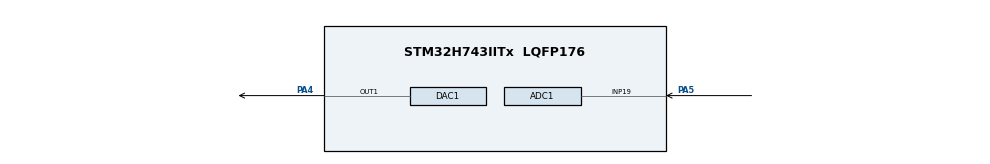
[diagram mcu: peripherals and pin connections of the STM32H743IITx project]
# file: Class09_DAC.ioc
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ADC1.Channel-3\#ChannelRegularConversion=ADC_CHANNEL_19
ADC1.ContinuousConvMode=DISABLE
ADC1.DiscontinuousConvMode=DISABLE
ADC1.NbrOfConversionFlag=1
ADC1.OffsetNumber-3\#ChannelRegularConversion=ADC_OFFSET_NONE
ADC1.Rank-3\#ChannelRegularConversion=1
ADC1.SamplingTime-3\#ChannelRegularConversion=ADC_SAMPLETIME_810CYCLES_5
ADC1.master=1
Mcu.Family=STM32H7
Mcu.Name=STM32H743IITx
Mcu.Package=LQFP176
NVIC.PriorityGroup=NVIC_PRIORITYGROUP_4
PA4.Signal=COMP_DAC11_group
PA5.Signal=ADCx_INP19
PH0-OSC_IN\ (PH0).Mode=HSE-External-Oscillator
PH0-OSC_IN\ (PH0).Signal=RCC_OSC_IN
PH1-OSC_OUT\ (PH1).Mode=HSE-External-Oscillator
PH1-OSC_OUT\ (PH1).Signal=RCC_OSC_OUT
ProjectManager.HeapSize=0x200
ProjectManager.StackSize=0x400
ProjectManager.TargetToolchain=MDK-ARM V5
RCC.ADCFreq_Value=150000000
RCC.APB1Freq_Value=100000000
RCC.APB2Freq_Value=100000000
RCC.APB3Freq_Value=100000000
RCC.APB4Freq_Value=100000000
RCC.CortexFreq_Value=400000000
RCC.D1PPRE=RCC_APB3_DIV2
RCC.D2PPRE1=RCC_APB1_DIV2
RCC.D2PPRE2=RCC_APB2_DIV2
RCC.D3PPRE=RCC_APB4_DIV2
RCC.DIVM1=2
RCC.DIVM2=2
RCC.DIVN1=64
RCC.DIVN2=12
RCC.DIVP2=1
RCC.HCLKFreq_Value=200000000
RCC.HPRE=RCC_HCLK_DIV2
RCC.PLLSourceVirtual=RCC_PLLSOURCE_HSE
RCC.SYSCLKFreq_VALUE=400000000
RCC.SYSCLKSource=RCC_SYSCLKSOURCE_PLLCLK
RCC.USBFreq_Value=400000000
SH.ADCx_INP19.0=ADC1_INP19,IN19-Single-Ended
SH.COMP_DAC11_group.0=DAC1_OUT1,DAC_OUT1
board=custom

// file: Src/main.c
/* USER CODE BEGIN Header */
/**
  ******************************************************************************
  * @file           : main.c
  * @brief          : Main program body
  ******************************************************************************
  ** This notice applies to any and all portions of this file
  * that are not between comment pairs USER CODE BEGIN and
  * USER CODE END. Other portions of this file, whether
  * inserted by the user or by software development tools
  * are owned by their respective copyright owners.
  *
  * COPYRIGHT(c) 2018 STMicroelectronics
  *
  * Redistribution and use in source and binary forms, with or without modification,
  * are permitted provided that the following conditions are met:
  *   1. Redistributions of source code must retain the above copyright notice,
  *      this list of conditions and the following disclaimer.
  *   2. Redistributions in binary form must reproduce the above copyright notice,
  *      this list of conditions and the following disclaimer in the documentation
  *      and/or other materials provided with the distribution.
  *   3. Neither the name of STMicroelectronics nor the names of its contributors
  *      may be used to endorse or promote products derived from this software
  *      without specific prior written permission.
  *
  * THIS SOFTWARE IS PROVIDED BY THE COPYRIGHT HOLDERS AND CONTRIBUTORS "AS IS"
  * AND ANY EXPRESS OR IMPLIED WARRANTIES, INCLUDING, BUT NOT LIMITED TO, THE
  * IMPLIED WARRANTIES OF MERCHANTABILITY AND FITNESS FOR A PARTICULAR PURPOSE ARE
  * DISCLAIMED. IN NO EVENT SHALL THE COPYRIGHT HOLDER OR CONTRIBUTORS BE LIABLE
  * FOR ANY DIRECT, INDIRECT, INCIDENTAL, SPECIAL, EXEMPLARY, OR CONSEQUENTIAL
  * DAMAGES (INCLUDING, BUT NOT LIMITED TO, PROCUREMENT OF SUBSTITUTE GOODS OR
  * SERVICES; LOSS OF USE, DATA, OR PROFITS; OR BUSINESS INTERRUPTION) HOWEVER
  * CAUSED AND ON ANY THEORY OF LIABILITY, WHETHER IN CONTRACT, STRICT LIABILITY,
  * OR TORT (INCLUDING NEGLIGENCE OR OTHERWISE) ARISING IN ANY WAY OUT OF THE USE
  * OF THIS SOFTWARE, EVEN IF ADVISED OF THE POSSIBILITY OF SUCH DAMAGE.
  *
  ******************************************************************************
  */
/* USER CODE END Header */

#include "main.h"

ADC_HandleTypeDef hadc1;

DAC_HandleTypeDef hdac1;

void SystemClock_Config(void);
static void MX_GPIO_Init(void);
static void MX_DAC1_Init(void);
static void MX_ADC1_Init(void);

/* USER CODE BEGIN 0 */
unsigned int adc_v;
unsigned int dac_v = 0;
float v;
/* USER CODE END 0 */

int main(void)
{

  /* MCU Configuration--------------------------------------------------------*/

  /* Reset of all peripherals, Initializes the Flash interface and the Systick. */
  HAL_Init();

  /* Configure the system clock */
  SystemClock_Config();

  /* Initialize all configured peripherals */
  MX_GPIO_Init();
  MX_DAC1_Init();
  MX_ADC1_Init();
  /* USER CODE BEGIN 2 */
	HAL_DAC_Start(&hdac1,DAC_CHANNEL_1);
  /* USER CODE END 2 */

  /* Infinite loop */
  while (1)
  {

    /* USER CODE BEGIN 3 */
		dac_v += 1;
		HAL_DAC_SetValue(&hdac1,DAC1_CHANNEL_1,DAC_ALIGN_12B_R,dac_v);
		HAL_ADC_Start(&hadc1);
		adc_v = HAL_ADC_GetValue(&hadc1);
		v = 3.3 * (adc_v / 65536.0);
  }
  /* USER CODE END 3 */
}

void SystemClock_Config(void)
{
  RCC_OscInitTypeDef RCC_OscInitStruct = {0};
  RCC_ClkInitTypeDef RCC_ClkInitStruct = {0};
  RCC_PeriphCLKInitTypeDef PeriphClkInitStruct = {0};

  /**Supply configuration update enable
  */
  MODIFY_REG(PWR->CR3, PWR_CR3_SCUEN, 0);
  /**Configure the main internal regulator output voltage
  */
  __HAL_PWR_VOLTAGESCALING_CONFIG(PWR_REGULATOR_VOLTAGE_SCALE1);

  while ((PWR->D3CR & (PWR_D3CR_VOSRDY)) != PWR_D3CR_VOSRDY)
  {

  }
  /**Macro to configure the PLL clock source
  */
  __HAL_RCC_PLL_PLLSOURCE_CONFIG(RCC_PLLSOURCE_HSE);
  /**Initializes the CPU, AHB and APB busses clocks
  */
  RCC_OscInitStruct.OscillatorType = RCC_OSCILLATORTYPE_HSE;
  RCC_OscInitStruct.HSEState = RCC_HSE_ON;
  RCC_OscInitStruct.PLL.PLLState = RCC_PLL_ON;
  RCC_OscInitStruct.PLL.PLLSource = RCC_PLLSOURCE_HSE;
  RCC_OscInitStruct.PLL.PLLM = 2;
  RCC_OscInitStruct.PLL.PLLN = 64;
  RCC_OscInitStruct.PLL.PLLP = 2;
  RCC_OscInitStruct.PLL.PLLQ = 2;
  RCC_OscInitStruct.PLL.PLLR = 2;
  RCC_OscInitStruct.PLL.PLLRGE = RCC_PLL1VCIRANGE_3;
  RCC_OscInitStruct.PLL.PLLVCOSEL = RCC_PLL1VCOWIDE;
  RCC_OscInitStruct.PLL.PLLFRACN = 0;
  if (HAL_RCC_OscConfig(&RCC_OscInitStruct) != HAL_OK)
  {
    Error_Handler();
  }
  /**Initializes the CPU, AHB and APB busses clocks
  */
  RCC_ClkInitStruct.ClockType = RCC_CLOCKTYPE_HCLK|RCC_CLOCKTYPE_SYSCLK
                              |RCC_CLOCKTYPE_PCLK1|RCC_CLOCKTYPE_PCLK2
                              |RCC_CLOCKTYPE_D3PCLK1|RCC_CLOCKTYPE_D1PCLK1;
  RCC_ClkInitStruct.SYSCLKSource = RCC_SYSCLKSOURCE_PLLCLK;
  RCC_ClkInitStruct.SYSCLKDivider = RCC_SYSCLK_DIV1;
  RCC_ClkInitStruct.AHBCLKDivider = RCC_HCLK_DIV2;
  RCC_ClkInitStruct.APB3CLKDivider = RCC_APB3_DIV2;
  RCC_ClkInitStruct.APB1CLKDivider = RCC_APB1_DIV2;
  RCC_ClkInitStruct.APB2CLKDivider = RCC_APB2_DIV2;
  RCC_ClkInitStruct.APB4CLKDivider = RCC_APB4_DIV2;

  if (HAL_RCC_ClockConfig(&RCC_ClkInitStruct, FLASH_LATENCY_2) != HAL_OK)
  {
    Error_Handler();
  }
  PeriphClkInitStruct.PeriphClockSelection = RCC_PERIPHCLK_ADC;
  PeriphClkInitStruct.PLL2.PLL2M = 2;
  PeriphClkInitStruct.PLL2.PLL2N = 12;
  PeriphClkInitStruct.PLL2.PLL2P = 1;
  PeriphClkInitStruct.PLL2.PLL2Q = 2;
  PeriphClkInitStruct.PLL2.PLL2R = 2;
  PeriphClkInitStruct.PLL2.PLL2RGE = RCC_PLL2VCIRANGE_3;
  PeriphClkInitStruct.PLL2.PLL2VCOSEL = RCC_PLL2VCOMEDIUM;
  PeriphClkInitStruct.PLL2.PLL2FRACN = 0;
  PeriphClkInitStruct.AdcClockSelection = RCC_ADCCLKSOURCE_PLL2;
  if (HAL_RCCEx_PeriphCLKConfig(&PeriphClkInitStruct) != HAL_OK)
  {
    Error_Handler();
  }
}

static void MX_ADC1_Init(void)
{

  ADC_MultiModeTypeDef multimode = {0};
  ADC_ChannelConfTypeDef sConfig = {0};

  /**Common config
  */
  hadc1.Instance = ADC1;
  hadc1.Init.ClockPrescaler = ADC_CLOCK_ASYNC_DIV6;
  hadc1.Init.Resolution = ADC_RESOLUTION_16B;
  hadc1.Init.ScanConvMode = ADC_SCAN_DISABLE;
  hadc1.Init.EOCSelection = ADC_EOC_SINGLE_CONV;
  hadc1.Init.LowPowerAutoWait = DISABLE;
  hadc1.Init.ContinuousConvMode = DISABLE;
  hadc1.Init.NbrOfConversion = 1;
  hadc1.Init.DiscontinuousConvMode = DISABLE;
  hadc1.Init.ExternalTrigConv = ADC_SOFTWARE_START;
  hadc1.Init.ExternalTrigConvEdge = ADC_EXTERNALTRIGCONVEDGE_NONE;
  hadc1.Init.ConversionDataManagement = ADC_CONVERSIONDATA_DR;
  hadc1.Init.Overrun = ADC_OVR_DATA_PRESERVED;
  hadc1.Init.LeftBitShift = ADC_LEFTBITSHIFT_NONE;
  hadc1.Init.BoostMode = DISABLE;
  hadc1.Init.OversamplingMode = DISABLE;
  if (HAL_ADC_Init(&hadc1) != HAL_OK)
  {
    Error_Handler();
  }
  /**Configure the ADC multi-mode
  */
  multimode.Mode = ADC_MODE_INDEPENDENT;
  if (HAL_ADCEx_MultiModeConfigChannel(&hadc1, &multimode) != HAL_OK)
  {
    Error_Handler();
  }
  /**Configure Regular Channel
  */
  sConfig.Channel = ADC_CHANNEL_19;
  sConfig.Rank = ADC_REGULAR_RANK_1;
  sConfig.SamplingTime = ADC_SAMPLETIME_810CYCLES_5;
  sConfig.SingleDiff = ADC_SINGLE_ENDED;
  sConfig.OffsetNumber = ADC_OFFSET_NONE;
  sConfig.Offset = 0;
  if (HAL_ADC_ConfigChannel(&hadc1, &sConfig) != HAL_OK)
  {
    Error_Handler();
  }

}

static void MX_DAC1_Init(void)
{

  DAC_ChannelConfTypeDef sConfig = {0};

  /**DAC Initialization
  */
  hdac1.Instance = DAC1;
  if (HAL_DAC_Init(&hdac1) != HAL_OK)
  {
    Error_Handler();
  }
  /**DAC channel OUT1 config
  */
  sConfig.DAC_SampleAndHold = DAC_SAMPLEANDHOLD_DISABLE;
  sConfig.DAC_Trigger = DAC_TRIGGER_NONE;
  sConfig.DAC_OutputBuffer = DAC_OUTPUTBUFFER_ENABLE;
  sConfig.DAC_ConnectOnChipPeripheral = DAC_CHIPCONNECT_DISABLE;
  sConfig.DAC_UserTrimming = DAC_TRIMMING_FACTORY;
  if (HAL_DAC_ConfigChannel(&hdac1, &sConfig, DAC_CHANNEL_1) != HAL_OK)
  {
    Error_Handler();
  }

}

static void MX_GPIO_Init(void)
{

  /* GPIO Ports Clock Enable */
  __HAL_RCC_GPIOH_CLK_ENABLE();
  __HAL_RCC_GPIOA_CLK_ENABLE();

}

void Error_Handler(void)
{
}

/************************ (C) COPYRIGHT STMicroelectronics *****END OF FILE****/
